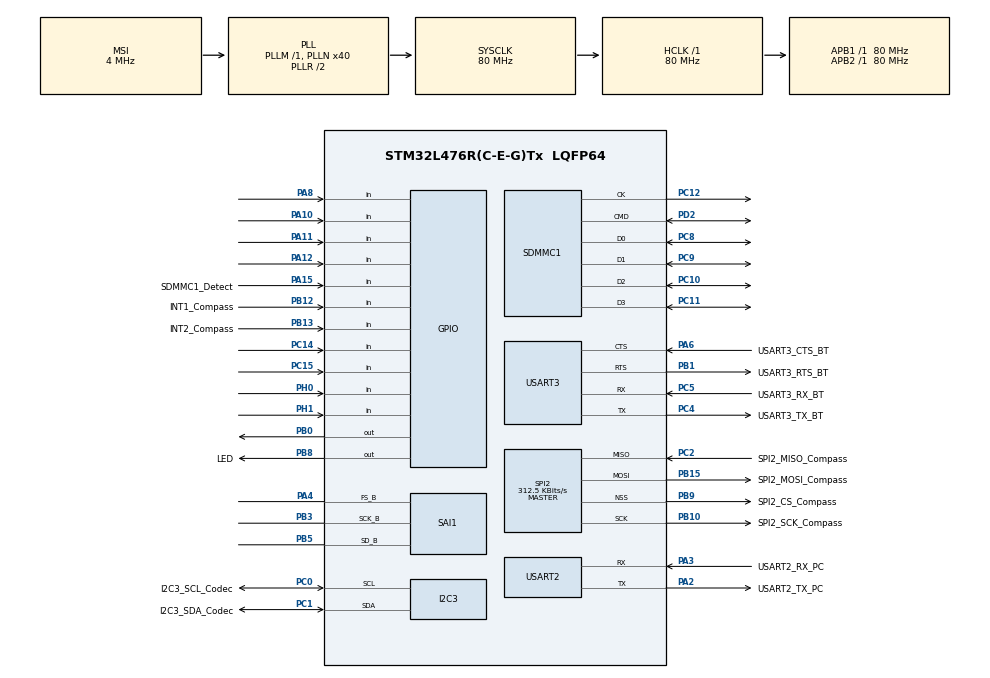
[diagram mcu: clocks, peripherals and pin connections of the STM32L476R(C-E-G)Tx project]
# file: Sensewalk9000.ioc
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FREERTOS.Tasks01=defaultTask,0,128,StartDefaultTask,Default
Mcu.Family=STM32L4
Mcu.Name=STM32L476R(C-E-G)Tx
Mcu.Package=LQFP64
NVIC.PriorityGroup=NVIC_PRIORITYGROUP_4
NVIC.TIM1_UP_TIM16_IRQn=true\:0\:0\:false
NVIC.TimeBase=TIM1_UP_TIM16_IRQn
NVIC.TimeBaseIP=TIM1
PA10.Signal=GPIO_Input
PA11.Signal=GPIO_Input
PA12.Signal=GPIO_Input
PA13.Mode=Serial-Wire
PA13.Signal=SYS_JTMS-SWDIO
PA14.Mode=Serial-Wire
PA14.Signal=SYS_JTCK-SWCLK
PA15.GPIO_Label=SDMMC1_Detect
PA15.Signal=GPIO_Input
PA2.GPIO_Label=USART2_TX_PC
PA2.Mode=Asynchronous
PA2.Signal=USART2_TX
PA3.GPIO_Label=USART2_RX_PC
PA3.Mode=Asynchronous
PA3.Signal=USART2_RX
PA4.Mode=SAI_B_Master
PA4.Signal=SAI1_FS_B
PA6.GPIO_Label=USART3_CTS_BT
PA6.Mode=CTS_RTS
PA6.Signal=USART3_CTS
PA8.Signal=GPIO_Input
PB0.Signal=GPIO_Output
PB1.GPIO_Label=USART3_RTS_BT
PB1.Mode=CTS_RTS
PB1.Signal=USART3_RTS
PB10.GPIO_Label=SPI2_SCK_Compass
PB10.Mode=Full_Duplex_Master
PB10.Signal=SPI2_SCK
PB12.GPIO_Label=INT1_Compass
PB12.Signal=GPIO_Input
PB13.GPIO_Label=INT2_Compass
PB13.Signal=GPIO_Input
PB15.GPIO_Label=SPI2_MOSI_Compass
PB15.Mode=Full_Duplex_Master
PB15.Signal=SPI2_MOSI
PB3.Mode=SAI_B_Master
PB3.Signal=SAI1_SCK_B
PB5.Mode=SAI_B_Master
PB5.Signal=SAI1_SD_B
PB8.GPIO_Label=LED
PB8.Signal=GPIO_Output
PB9.GPIO_Label=SPI2_CS_Compass
PB9.Mode=NSS_Signal_Hard_Output
PB9.Signal=SPI2_NSS
PC0.GPIO_Label=I2C3_SCL_Codec
PC0.Mode=I2C
PC0.Signal=I2C3_SCL
PC1.GPIO_Label=I2C3_SDA_Codec
PC1.Mode=I2C
PC1.Signal=I2C3_SDA
PC10.Mode=SD_4_bits_Wide_bus
PC10.Signal=SDMMC1_D2
PC11.Mode=SD_4_bits_Wide_bus
PC11.Signal=SDMMC1_D3
PC12.Mode=SD_4_bits_Wide_bus
PC12.Signal=SDMMC1_CK
PC13.Mode=SYS-WakeUp2
PC13.Signal=SYS_WKUP2
PC14/OSC32_IN.Signal=GPIO_Input
PC15/OSC32_OUT.Signal=GPIO_Input
PC2.GPIO_Label=SPI2_MISO_Compass
PC2.Mode=Full_Duplex_Master
PC2.Signal=SPI2_MISO
PC4.GPIO_Label=USART3_TX_BT
PC4.Mode=Asynchronous
PC4.Signal=USART3_TX
PC5.GPIO_Label=USART3_RX_BT
PC5.Mode=Asynchronous
PC5.Signal=USART3_RX
PC8.Mode=SD_4_bits_Wide_bus
PC8.Signal=SDMMC1_D0
PC9.Mode=SD_4_bits_Wide_bus
PC9.Signal=SDMMC1_D1
PD2.Mode=SD_4_bits_Wide_bus
PD2.Signal=SDMMC1_CMD
PH0/OSC_IN.Signal=GPIO_Input
PH1/OSC_OUT.Signal=GPIO_Input
ProjectManager.HeapSize=0x400
ProjectManager.StackSize=0x200
ProjectManager.TargetToolchain=SW4STM32
RCC.ADCFreq_Value=32000000
RCC.AHBFreq_Value=80000000
RCC.APB1Freq_Value=80000000
RCC.APB1TimFreq_Value=80000000
RCC.APB2Freq_Value=80000000
RCC.APB2TimFreq_Value=80000000
RCC.CortexFreq_Value=80000000
RCC.HCLKFreq_Value=80000000
RCC.HSE_VALUE=8000000
RCC.HSI_VALUE=16000000
RCC.LSE_VALUE=32768
RCC.MSI_VALUE=4000000
RCC.PLLN=40
RCC.PLLSAI1N=16
RCC.SYSCLKFreq_VALUE=80000000
RCC.SYSCLKSource=RCC_SYSCLKSOURCE_PLLCLK
RCC.USBFreq_Value=32000000
RCC.VCOOutputFreq_Value=160000000
SAI1.InitProtocol-SAI_B_Master=Enable
SAI1.Instance-SAI_B_Master=SAI$Index_Block_B
SAI1.VirtualProtocol-SAI_B_BASIC=VM_BASIC_PROTOCOL
SDMMC1.BusWide=SDMMC_BUS_WIDE_1B
SDMMC1.WideMode=SDMMC_BUS_WIDE_4B
SPI2.BaudRatePrescaler=SPI_BAUDRATEPRESCALER_256
SPI2.CLKPhase=SPI_PHASE_2EDGE
SPI2.CLKPolarity=SPI_POLARITY_HIGH
SPI2.CalculateBaudRate=312.5 KBits/s
SPI2.DataSize=SPI_DATASIZE_8BIT
SPI2.Mode=SPI_MODE_MASTER
SPI2.VirtualNSS=VM_NSSHARD
VP_FATFS_VS_SDIO.Mode=SDIO
VP_FREERTOS_VS_ENABLE.Mode=Enabled
VP_SAI1_VP_$IpInstance_SAIB_SAI_BASIC.Mode=SAI_B_BASIC
VP_SYS_VS_tim1.Mode=TIM1
board=Sensewalk9000

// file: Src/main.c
/**
  ******************************************************************************
  * File Name          : main.c
  * Description        : Main program body
  ******************************************************************************
  *
  * COPYRIGHT(c) 2016 STMicroelectronics
  *
  * Redistribution and use in source and binary forms, with or without modification,
  * are permitted provided that the following conditions are met:
  *   1. Redistributions of source code must retain the above copyright notice,
  *      this list of conditions and the following disclaimer.
  *   2. Redistributions in binary form must reproduce the above copyright notice,
  *      this list of conditions and the following disclaimer in the documentation
  *      and/or other materials provided with the distribution.
  *   3. Neither the name of STMicroelectronics nor the names of its contributors
  *      may be used to endorse or promote products derived from this software
  *      without specific prior written permission.
  *
  * THIS SOFTWARE IS PROVIDED BY THE COPYRIGHT HOLDERS AND CONTRIBUTORS "AS IS"
  * AND ANY EXPRESS OR IMPLIED WARRANTIES, INCLUDING, BUT NOT LIMITED TO, THE
  * IMPLIED WARRANTIES OF MERCHANTABILITY AND FITNESS FOR A PARTICULAR PURPOSE ARE
  * DISCLAIMED. IN NO EVENT SHALL THE COPYRIGHT HOLDER OR CONTRIBUTORS BE LIABLE
  * FOR ANY DIRECT, INDIRECT, INCIDENTAL, SPECIAL, EXEMPLARY, OR CONSEQUENTIAL
  * DAMAGES (INCLUDING, BUT NOT LIMITED TO, PROCUREMENT OF SUBSTITUTE GOODS OR
  * SERVICES; LOSS OF USE, DATA, OR PROFITS; OR BUSINESS INTERRUPTION) HOWEVER
  * CAUSED AND ON ANY THEORY OF LIABILITY, WHETHER IN CONTRACT, STRICT LIABILITY,
  * OR TORT (INCLUDING NEGLIGENCE OR OTHERWISE) ARISING IN ANY WAY OUT OF THE USE
  * OF THIS SOFTWARE, EVEN IF ADVISED OF THE POSSIBILITY OF SUCH DAMAGE.
  *
  ******************************************************************************
  */
#include "stm32l4xx_hal.h"
#include "cmsis_os.h"
#include "fatfs.h"

I2C_HandleTypeDef hi2c3;

SAI_HandleTypeDef hsai_BlockB1;

SD_HandleTypeDef hsd1;
HAL_SD_CardInfoTypedef SDCardInfo1;

SPI_HandleTypeDef hspi2;

UART_HandleTypeDef huart2;
UART_HandleTypeDef huart3;

osThreadId defaultTaskHandle;

/* USER CODE BEGIN PV */
/* Private variables ---------------------------------------------------------*/

/* USER CODE END PV */

void SystemClock_Config(void);
static void MX_GPIO_Init(void);
static void MX_SDMMC1_SD_Init(void);
static void MX_USART2_UART_Init(void);
static void MX_USART3_UART_Init(void);
static void MX_SPI2_Init(void);
static void MX_I2C3_Init(void);
static void MX_SAI1_Init(void);
void StartDefaultTask(void const * argument);

/* USER CODE BEGIN PFP */
/* Private function prototypes -----------------------------------------------*/

/* USER CODE END PFP */

int main(void)
{

  /* MCU Configuration----------------------------------------------------------*/

  /* Reset of all peripherals, Initializes the Flash interface and the Systick. */
  HAL_Init();

  /* Configure the system clock */
  SystemClock_Config();

  /* Initialize all configured peripherals */
  MX_GPIO_Init();
  MX_SDMMC1_SD_Init();
  MX_USART2_UART_Init();
  MX_USART3_UART_Init();
  MX_SPI2_Init();
  MX_FATFS_Init();
  MX_I2C3_Init();
  MX_SAI1_Init();

  /* Create the thread(s) */
  /* definition and creation of defaultTask */
  osThreadDef(defaultTask, StartDefaultTask, osPriorityNormal, 0, 128);
  defaultTaskHandle = osThreadCreate(osThread(defaultTask), NULL);

  /* Start scheduler */
  osKernelStart();

  /* We should never get here as control is now taken by the scheduler */

  /* Infinite loop */
  while (1)
  {

  }

}

/** System Clock Configuration
*/
void SystemClock_Config(void)
{

  RCC_OscInitTypeDef RCC_OscInitStruct;
  RCC_ClkInitTypeDef RCC_ClkInitStruct;
  RCC_PeriphCLKInitTypeDef PeriphClkInit;

  RCC_OscInitStruct.OscillatorType = RCC_OSCILLATORTYPE_MSI;
  RCC_OscInitStruct.MSIState = RCC_MSI_ON;
  RCC_OscInitStruct.MSICalibrationValue = 0;
  RCC_OscInitStruct.MSIClockRange = RCC_MSIRANGE_6;
  RCC_OscInitStruct.PLL.PLLState = RCC_PLL_ON;
  RCC_OscInitStruct.PLL.PLLSource = RCC_PLLSOURCE_MSI;
  RCC_OscInitStruct.PLL.PLLM = 1;
  RCC_OscInitStruct.PLL.PLLN = 40;
  RCC_OscInitStruct.PLL.PLLP = RCC_PLLP_DIV7;
  RCC_OscInitStruct.PLL.PLLQ = RCC_PLLQ_DIV2;
  RCC_OscInitStruct.PLL.PLLR = RCC_PLLR_DIV2;
  HAL_RCC_OscConfig(&RCC_OscInitStruct);

  RCC_ClkInitStruct.ClockType = RCC_CLOCKTYPE_HCLK|RCC_CLOCKTYPE_SYSCLK
                              |RCC_CLOCKTYPE_PCLK1|RCC_CLOCKTYPE_PCLK2;
  RCC_ClkInitStruct.SYSCLKSource = RCC_SYSCLKSOURCE_PLLCLK;
  RCC_ClkInitStruct.AHBCLKDivider = RCC_SYSCLK_DIV1;
  RCC_ClkInitStruct.APB1CLKDivider = RCC_HCLK_DIV1;
  RCC_ClkInitStruct.APB2CLKDivider = RCC_HCLK_DIV1;
  HAL_RCC_ClockConfig(&RCC_ClkInitStruct, FLASH_LATENCY_4);

  PeriphClkInit.PeriphClockSelection = RCC_PERIPHCLK_USART2|RCC_PERIPHCLK_USART3
                              |RCC_PERIPHCLK_SAI1|RCC_PERIPHCLK_I2C3
                              |RCC_PERIPHCLK_SDMMC1;
  PeriphClkInit.Usart2ClockSelection = RCC_USART2CLKSOURCE_PCLK1;
  PeriphClkInit.Usart3ClockSelection = RCC_USART3CLKSOURCE_PCLK1;
  PeriphClkInit.I2c3ClockSelection = RCC_I2C3CLKSOURCE_PCLK1;
  PeriphClkInit.Sai1ClockSelection = RCC_SAI1CLKSOURCE_PLLSAI1;
  PeriphClkInit.Sdmmc1ClockSelection = RCC_SDMMC1CLKSOURCE_PLLSAI1;
  PeriphClkInit.PLLSAI1.PLLSAI1N = 16;
  PeriphClkInit.PLLSAI1.PLLSAI1P = RCC_PLLP_DIV7;
  PeriphClkInit.PLLSAI1.PLLSAI1Q = RCC_PLLQ_DIV2;
  PeriphClkInit.PLLSAI1.PLLSAI1R = RCC_PLLR_DIV2;
  PeriphClkInit.PLLSAI1.PLLSAI1ClockOut = RCC_PLLSAI1_SAI1CLK|RCC_PLLSAI1_48M2CLK;
  HAL_RCCEx_PeriphCLKConfig(&PeriphClkInit);

  __PWR_CLK_ENABLE();

  HAL_PWREx_ControlVoltageScaling(PWR_REGULATOR_VOLTAGE_SCALE1);

  HAL_SYSTICK_Config(HAL_RCC_GetHCLKFreq()/1000);

  HAL_SYSTICK_CLKSourceConfig(SYSTICK_CLKSOURCE_HCLK);

  /* SysTick_IRQn interrupt configuration */
  HAL_NVIC_SetPriority(SysTick_IRQn, 15, 0);
}

/* I2C3 init function */
void MX_I2C3_Init(void)
{

  hi2c3.Instance = I2C3;
  hi2c3.Init.Timing = 0x00000000;
  hi2c3.Init.OwnAddress1 = 0;
  hi2c3.Init.AddressingMode = I2C_ADDRESSINGMODE_7BIT;
  hi2c3.Init.DualAddressMode = I2C_DUALADDRESS_DISABLED;
  hi2c3.Init.OwnAddress2 = 0;
  hi2c3.Init.OwnAddress2Masks = I2C_OA2_NOMASK;
  hi2c3.Init.GeneralCallMode = I2C_GENERALCALL_DISABLED;
  hi2c3.Init.NoStretchMode = I2C_NOSTRETCH_DISABLED;
  HAL_I2C_Init(&hi2c3);

    /**Configure Analogue filter
    */
  HAL_I2CEx_AnalogFilter_Config(&hi2c3, I2C_ANALOGFILTER_ENABLED);

}

/* SAI1 init function */
void MX_SAI1_Init(void)
{

  hsai_BlockB1.Instance = SAI1_Block_B;
  hsai_BlockB1.Init.AudioMode = SAI_MODEMASTER_TX;
  hsai_BlockB1.Init.Synchro = SAI_ASYNCHRONOUS;
  hsai_BlockB1.Init.OutputDrive = SAI_OUTPUTDRIVE_DISABLED;
  hsai_BlockB1.Init.NoDivider = SAI_MASTERDIVIDER_ENABLED;
  hsai_BlockB1.Init.FIFOThreshold = SAI_FIFOTHRESHOLD_EMPTY;
  hsai_BlockB1.Init.AudioFrequency = SAI_AUDIO_FREQUENCY_192K;
  hsai_BlockB1.Init.SynchroExt = SAI_SYNCEXT_DISABLE;
  hsai_BlockB1.Init.MonoStereoMode = SAI_STEREOMODE;
  hsai_BlockB1.Init.CompandingMode = SAI_NOCOMPANDING;
  hsai_BlockB1.Init.TriState = SAI_OUTPUT_NOTRELEASED;
  HAL_SAI_InitProtocol(&hsai_BlockB1, SAI_I2S_STANDARD, SAI_PROTOCOL_DATASIZE_16BIT, 2);

}

/* SDMMC1 init function */
void MX_SDMMC1_SD_Init(void)
{

  hsd1.Instance = SDMMC1;
  hsd1.Init.ClockEdge = SDMMC_CLOCK_EDGE_RISING;
  hsd1.Init.ClockBypass = SDMMC_CLOCK_BYPASS_DISABLE;
  hsd1.Init.ClockPowerSave = SDMMC_CLOCK_POWER_SAVE_DISABLE;
  hsd1.Init.BusWide = SDMMC_BUS_WIDE_1B;
  hsd1.Init.HardwareFlowControl = SDMMC_HARDWARE_FLOW_CONTROL_DISABLE;
  hsd1.Init.ClockDiv = 0;
  HAL_SD_Init(&hsd1, &SDCardInfo1);

  HAL_SD_WideBusOperation_Config(&hsd1, SDMMC_BUS_WIDE_4B);

}

/* SPI2 init function */
void MX_SPI2_Init(void)
{

  hspi2.Instance = SPI2;
  hspi2.Init.Mode = SPI_MODE_MASTER;
  hspi2.Init.Direction = SPI_DIRECTION_2LINES;
  hspi2.Init.DataSize = SPI_DATASIZE_8BIT;
  hspi2.Init.CLKPolarity = SPI_POLARITY_HIGH;
  hspi2.Init.CLKPhase = SPI_PHASE_2EDGE;
  hspi2.Init.NSS = SPI_NSS_HARD_OUTPUT;
  hspi2.Init.BaudRatePrescaler = SPI_BAUDRATEPRESCALER_256;
  hspi2.Init.FirstBit = SPI_FIRSTBIT_MSB;
  hspi2.Init.TIMode = SPI_TIMODE_DISABLED;
  hspi2.Init.CRCCalculation = SPI_CRCCALCULATION_DISABLED;
  hspi2.Init.CRCPolynomial = 7;
  hspi2.Init.CRCLength = SPI_CRC_LENGTH_DATASIZE;
  hspi2.Init.NSSPMode = SPI_NSS_PULSE_DISABLED;
  HAL_SPI_Init(&hspi2);

}

/* USART2 init function */
void MX_USART2_UART_Init(void)
{

  huart2.Instance = USART2;
  huart2.Init.BaudRate = 115200;
  huart2.Init.WordLength = UART_WORDLENGTH_7B;
  huart2.Init.StopBits = UART_STOPBITS_1;
  huart2.Init.Parity = UART_PARITY_NONE;
  huart2.Init.Mode = UART_MODE_TX_RX;
  huart2.Init.HwFlowCtl = UART_HWCONTROL_NONE;
  huart2.Init.OverSampling = UART_OVERSAMPLING_16;
  huart2.Init.OneBitSampling = UART_ONEBIT_SAMPLING_DISABLED;
  huart2.AdvancedInit.AdvFeatureInit = UART_ADVFEATURE_NO_INIT;
  HAL_UART_Init(&huart2);

}

/* USART3 init function */
void MX_USART3_UART_Init(void)
{

  huart3.Instance = USART3;
  huart3.Init.BaudRate = 115200;
  huart3.Init.WordLength = UART_WORDLENGTH_7B;
  huart3.Init.StopBits = UART_STOPBITS_1;
  huart3.Init.Parity = UART_PARITY_NONE;
  huart3.Init.Mode = UART_MODE_TX_RX;
  huart3.Init.HwFlowCtl = UART_HWCONTROL_RTS_CTS;
  huart3.Init.OverSampling = UART_OVERSAMPLING_16;
  huart3.Init.OneBitSampling = UART_ONEBIT_SAMPLING_DISABLED;
  huart3.AdvancedInit.AdvFeatureInit = UART_ADVFEATURE_NO_INIT;
  HAL_UART_Init(&huart3);

}

/** Configure pins as
        * Analog
        * Input
        * Output
        * EVENT_OUT
        * EXTI
*/
void MX_GPIO_Init(void)
{

  GPIO_InitTypeDef GPIO_InitStruct;

  /* GPIO Ports Clock Enable */
  __GPIOC_CLK_ENABLE();
  __GPIOH_CLK_ENABLE();
  __GPIOA_CLK_ENABLE();
  __GPIOB_CLK_ENABLE();
  __GPIOD_CLK_ENABLE();

  /*Configure GPIO pins : PC14 PC15 */
  GPIO_InitStruct.Pin = GPIO_PIN_14|GPIO_PIN_15;
  GPIO_InitStruct.Mode = GPIO_MODE_INPUT;
  GPIO_InitStruct.Pull = GPIO_NOPULL;
  HAL_GPIO_Init(GPIOC, &GPIO_InitStruct);

  /*Configure GPIO pins : PH0 PH1 */
  GPIO_InitStruct.Pin = GPIO_PIN_0|GPIO_PIN_1;
  GPIO_InitStruct.Mode = GPIO_MODE_INPUT;
  GPIO_InitStruct.Pull = GPIO_NOPULL;
  HAL_GPIO_Init(GPIOH, &GPIO_InitStruct);

  /*Configure GPIO pins : PB0 LED_Pin */
  GPIO_InitStruct.Pin = GPIO_PIN_0|LED_Pin;
  GPIO_InitStruct.Mode = GPIO_MODE_OUTPUT_PP;
  GPIO_InitStruct.Pull = GPIO_NOPULL;
  GPIO_InitStruct.Speed = GPIO_SPEED_LOW;
  HAL_GPIO_Init(GPIOB, &GPIO_InitStruct);

  /*Configure GPIO pins : INT1_Compass_Pin INT2_Compass_Pin */
  GPIO_InitStruct.Pin = INT1_Compass_Pin|INT2_Compass_Pin;
  GPIO_InitStruct.Mode = GPIO_MODE_INPUT;
  GPIO_InitStruct.Pull = GPIO_NOPULL;
  HAL_GPIO_Init(GPIOB, &GPIO_InitStruct);

  /*Configure GPIO pins : PA8 PA10 PA11 PA12
                           SDMMC1_Detect_Pin */
  GPIO_InitStruct.Pin = GPIO_PIN_8|GPIO_PIN_10|GPIO_PIN_11|GPIO_PIN_12
                          |SDMMC1_Detect_Pin;
  GPIO_InitStruct.Mode = GPIO_MODE_INPUT;
  GPIO_InitStruct.Pull = GPIO_NOPULL;
  HAL_GPIO_Init(GPIOA, &GPIO_InitStruct);

  /*Configure GPIO pin Output Level */
  HAL_GPIO_WritePin(GPIOB, GPIO_PIN_0|LED_Pin, GPIO_PIN_RESET);

}

/* StartDefaultTask function */
void StartDefaultTask(void const * argument)
{
  /* init code for FATFS */
  MX_FATFS_Init();

  /* USER CODE BEGIN 5 */
  /* Infinite loop */
  for(;;)
  {
	  HAL_GPIO_TogglePin(GPIOB, GPIO_PIN_8);
    osDelay(1);
  }
  /* USER CODE END 5 */
}

/************************ (C) COPYRIGHT STMicroelectronics *****END OF FILE****/
